# R7FA4L1BD register map
Vendor: Renesas Electronics Corporation; Series: RA4; File version: 0.90.02
CPU: CM33 r0p4, little endian, MPU, FPU, VTOR, 4 interrupt priority bits, 96 interrupts
Registers are 32-bit, read-write, reset 0x0 unless marked. A register's access mark holds for its fields unless they carry their own. Offsets are from the block's base; [hi:lo] are bit positions; 'fields as' and 'values as' point back to an identical list.

## SCI0 — Serial Communication Interface
Base 0x40118000
Same registers: SCI9 0x40118900
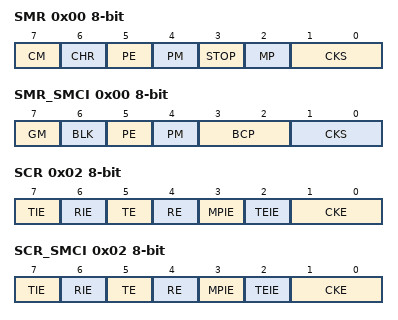
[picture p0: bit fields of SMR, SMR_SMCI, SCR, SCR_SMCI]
0x00 SMR 8-bit — Serial Mode Register for Non-Smart Card Interface Mode (SCMR.SMIF = 0)
  [7] CM — Communication Mode
    0=Asynchronous mode or simple IIC mode; 1=Clock synchronous mode or simple SPI mode
  [6] CHR — Character Length
    0=SCMR.CHR1 = 0: Transmit/receive in 9-bit data length SCMR.CHR1 = 1: Transmit/receive in 8-bit data length (initial value); 1=SCMR.CHR1 = 0: Transmit/receive in 9-bit data length SCMR.CHR1 = 1: Transmit/receive in 7-bit data length
  [5] PE — Parity Enable
    0=When transmitting: Do not add parity bit When receiving: Do not check parity bit; 1=When transmitting: Add parity bit When receiving: Check parity bit
  [4] PM — Parity Mode
    0=Even parity; 1=Odd parity
  [3] STOP — Stop Bit Length
    0=1 stop bit; 1=2 stop bits
  [2] MP — Multi-Processor Mode
    0=Disable multi-processor communications function; 1=Enable multi-processor communications function
  [1:0] CKS — Clock Select
    0=PCLK clock (n = 0); 1=PCLK/4 clock (n = 1); 2=PCLK/16 clock (n = 2); 3=PCLK/64 clock (n = 3)
0x00 SMR_SMCI 8-bit (alternate view of SMR) — Serial Mode Register for Smart Card Interface Mode (SCMR.SMIF = 1)
  [7] GM — GSM Mode
    0=Normal mode operation; 1=GSM mode operation
  [6] BLK — Block Transfer Mode
    0=Normal mode operation; 1=Block transfer mode operation
  [5] PE — Parity Enable
  [4] PM — Parity Mode
    0=Even parity; 1=Odd parity
  [3:2] BCP — Base Clock Pulse
  [1:0] CKS — Clock Select
    values as SMR.CKS
0x01 BRR 8-bit reset 0xFF — Bit Rate Register
0x02 SCR 8-bit — Serial Control Register for Non-Smart Card Interface Mode (SCMR.SMIF = 0)
  [7] TIE — Transmit Interrupt Enable
    0=Disable SCIn_TXI interrupt requests; 1=Enable SCIn_TXI interrupt requests
  [6] RIE — Receive Interrupt Enable
    0=Disable SCIn_RXI and SCIn_ERI interrupt requests; 1=Enable SCIn_RXI and SCIn_ERI interrupt requests
  [5] TE — Transmit Enable
    0=Disable serial transmission; 1=Enable serial transmission
  [4] RE — Receive Enable
    0=Disable serial reception; 1=Enable serial reception
  [3] MPIE — Multi-Processor Interrupt Enable
    0=Normal reception; 1=When data with the multi-processor bit set to 0 is received, the data is not read, and setting the status flags RDRF, ORER, and FER in SSR to 1 and the status flags SYER, PFER, and SBER in MESR are disabled. When data with the multi-processor bit set to 1 is received, the MPIE bit is automatically set to 0, and normal reception is resumed.
  [2] TEIE — Transmit End Interrupt Enable
    0=Disable SCIn_TEI interrupt requests; 1=Enable SCIn_TEI interrupt requests
  [1:0] CKE — Clock Enable
    0=In asynchronous mode, the SCKn pin is available for use as an I/O port based on the I/O port settings. In clock synchronous mode, the SCKn pin functions as the clock output pin.; 1=In asynchronous mode, a clock with the same frequency as the bit rate is output from the SCKn pin. In clock synchronous mode, the SCKn pin functions as the clock output pin.; other=Others (In asynchronous mode, input a clock with a frequency 16 times the bit rate from the SCKn pin when the SEMR.ABCS bit is 0. Input a clock signal with a frequency eight times the bit rate when the SEMR.ABCS bit is 1. The SCKn pin is available for use as an I/O port based on the I/O port settings when the GPT clock is used. In clock synchronous mode, the SCKn pin functions as the clock input pin.)
0x02 SCR_SMCI 8-bit (alternate view of SCR) — Serial Control Register for Smart Card Interface Mode (SCMR.SMIF = 1)
  [7] TIE — Transmit Interrupt Enable
    values as SCR.TIE
  [6] RIE — Receive Interrupt Enable
    values as SCR.RIE
  [5] TE — Transmit Enable
    0=Disable serial transmission; 1=Enable serial transmission
  [4] RE — Receive Enable
    0=Disable serial reception; 1=Enable serial reception
  [3] MPIE — Multi-Processor Interrupt Enable
  [2] TEIE — Transmit End Interrupt Enable
  [1:0] CKE — Clock Enable
    0=When SMR_SMCI.GM = 0: Disable output The SCKn pin is available for use as an I/O port if set up in the I/O port settings When SMR_SMCI.GM = 1: Fix output low; 1=When SMR_SMCI.GM = 0: Output clock When SMR_SMCI.GM = 1: Output clock; 2=When SMR_SMCI.GM = 0: Setting prohibited When SMR_SMCI.GM = 1: Fix output high; 3=When SMR_SMCI.GM = 0: Setting prohibited When SMR_SMCI.GM = 1: Output clock
0x03 TDR 8-bit reset 0xFF — Transmit Data Register
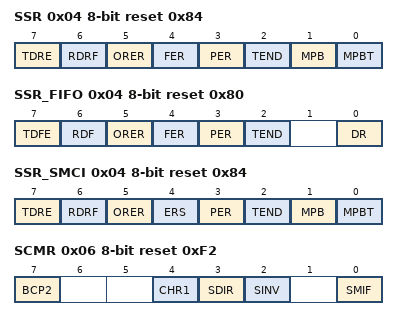
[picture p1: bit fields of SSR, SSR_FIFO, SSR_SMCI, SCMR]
0x04 SSR 8-bit reset 0x84 — Serial Status Register for Non-Smart Card Interface and Non-FIFO Mode (SCMR.SMIF = 0, FCR.FM = 0, and MMR.MANEN = 0)
  [7] TDRE — Transmit Data Empty Flag
    0=Transmit data in TDR register; 1=No transmit data in TDR register
  [6] RDRF — Receive Data Full Flag
    0=No received data in RDR register; 1=Received data in RDR register
  [5] ORER — Overrun Error Flag
    0=No overrun error occurred; 1=Overrun error occurred
  [4] FER — Framing Error Flag
    0=No framing error occurred; 1=Framing error occurred
  [3] PER — Parity Error Flag
    0=No parity error occurred; 1=Parity error occurred
  [2] TEND ro — Transmit End Flag
    0=A character is being transmitted; 1=Character transfer is complete
  [1] MPB ro — Multi-Processor
    0=Data transmission cycle; 1=ID transmission cycle
  [0] MPBT — Multi-Processor Bit Transfer
    0=Data transmission cycle; 1=ID transmission cycle
0x04 SSR_FIFO 8-bit reset 0x80 (alternate view of SSR) — Serial Status Register for Non-Smart Card Interface and FIFO Mode (SCMR.SMIF = 0, FCR.FM = 1, and MMR.MANEN = 0)
  [7] TDFE — Transmit FIFO Data Empty Flag
    0=The amount of transmit data written in FTDRHL exceeds the specified transmit triggering number; 1=The amount of transmit data written in FTDRHL is equal to or less than the specified transmit triggering number
  [6] RDF — Receive FIFO Data Full Flag
    0=The amount of receive data written in FRDRHL is less than the specified receive triggering number; 1=The amount of receive data written in FRDRHL is equal to or greater than the specified receive triggering number
  [5] ORER — Overrun Error Flag
    0=No overrun error occurred; 1=Overrun error occurred
  [4] FER — Framing Error Flag
    0=No framing error occurred; 1=Framing error occurred
  [3] PER — Parity Error Flag
    0=No parity error occurred; 1=Parity error occurred
  [2] TEND — Transmit End Flag
    values as SSR.TEND
  [0] DR — Receive Data Ready Flag
    0=Receiving is in progress, or no received data remains in FRDRHL after successfully completed reception (receive FIFO empty); 1=Next receive data is not received for a period after normal receiving is complete, when the amount of data stored in the FIFO is equal to or less than the receive triggering number
0x04 SSR_SMCI 8-bit reset 0x84 (alternate view of SSR) — Serial Status Register for Smart Card Interface Mode (SCMR.SMIF = 1, and MMR.MANEN = 0)
  [7] TDRE — Transmit Data Empty Flag
    values as SSR.TDRE
  [6] RDRF — Receive Data Full Flag
    values as SSR.RDRF
  [5] ORER — Overrun Error Flag
    0=No overrun error occurred; 1=Overrun error occurred
  [4] ERS — Error Signal Status Flag
    0=No low error signal response; 1=Low error signal response occurred
  [3] PER — Parity Error Flag
    0=No parity error occurred; 1=Parity error occurred
  [2] TEND ro — Transmit End Flag
    values as SSR.TEND
  [1] MPB ro — Multi-Processor
  [0] MPBT — Multi-Processor Bit Transfer
0x05 RDR 8-bit ro — Receive Data Register
0x06 SCMR 8-bit reset 0xF2 — Smart Card Mode Register
  [7] BCP2 — Base Clock Pulse 2
  [4] CHR1 — Character Length 1
    0=SMR.CHR = 0: Transmit/receive in 9-bit data length SMR.CHR = 1: Transmit/receive in 9-bit data length; 1=SMR.CHR = 0: Transmit/receive in 8-bit data length (initial value) SMR.CHR = 1: Transmit/receive in 7-bit data length
  [3] SDIR — Transmitted/Received Data Transfer Direction
    0=Transfer LSB-first; 1=Transfer MSB-first
  [2] SINV — Transmitted/Received Data Invert
    0=TDR contents are transmitted as they are. Received data is stored as received in the RDR register.; 1=TDR register contents are inverted before transmission. Receive data is stored in inverted form in the RDR register.
  [0] SMIF — Smart Card Interface Mode Select
    0=Non-smart card interface mode (asynchronous mode, clock synchronous mode, simple SPI mode, or simple IIC mode); 1=Smart card interface mode
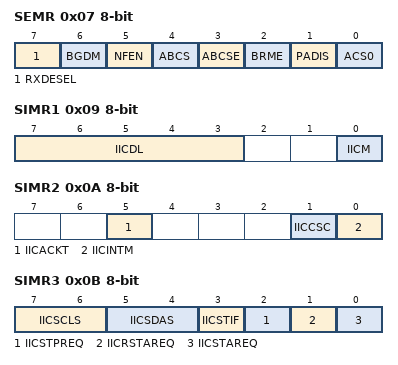
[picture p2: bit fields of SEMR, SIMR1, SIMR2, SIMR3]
0x07 SEMR 8-bit — Simple LIN Mode Register
  [7] RXDESEL — Asynchronous Start Bit Edge Detection Select
    0=Detect low level on RXDn pin as start bit; 1=Detect falling edge of RXDn pin as start bit
  [6] BGDM — Baud Rate Generator Double-Speed Mode Select
    0=Output clock from baud rate generator with normal frequency; 1=Output clock from baud rate generator with doubled frequency
  [5] NFEN — Digital Noise Filter Function Enable
    0=In asynchronous mode: Disable noise cancellation function for RXDn input signal In simple I2C mode: Disable noise cancellation function for SCLn and SDAn input signals; 1=In asynchronous mode: Enable noise cancellation function for RXDn input signal In simple I2C mode: Enable noise cancellation function for SCLn and SDAn input signals
  [4] ABCS — Asynchronous Mode Base Clock Select
    0=Select 16 base clock cycles for 1-bit period; 1=Select 8 base clock cycles for 1-bit period
  [3] ABCSE — Asynchronous Mode Extended Base Clock Select 1
    0=Clock cycles for 1-bit period determined by combination of the BGDM and ABCS bits in the SEMR register; 1=Baud rate is 6 base clock cycles for 1-bit period These bits for the other SCI channels than SCIn (n = 0, 3 to 5, 9) are reserved
  [2] BRME — Bit Rate Modulation Enable
    0=Disable bit rate modulation function; 1=Enable bit rate modulation function
  [1] PADIS — Preamble function Disable
    0=Preamble output function is enabled; 1=Preamble output function is disabled These bits for the other SCI channels than SCIn (n = 0, 3 to 5, 9) are reserved
  [0] ACS0 — Asynchronous Mode Clock Source Select
    0=External clock input; 1=Logical AND of compare matches output from the internal GPT. These bit for the other SCI channels than SCIn (n = 1) are reserved.
0x08 SNFR 8-bit — Noise Filter Setting Register
  [2:0] NFCS — Noise Filter Clock Select
    0=In asynchronous mode: Use clock signal divided by 1 with noise filter In simple I2C mode: Setting prohibited; 1=In asynchronous mode: Setting prohibited In simple I2C mode: Use clock signal divided by 1 with noise filter; 2=In asynchronous mode: Setting prohibited In simple I2C mode: Use clock signal divided by 2 with noise filter; 3=In asynchronous mode: Setting prohibited In simple I2C mode: Use clock signal divided by 4 with noise filter; 4=In asynchronous mode: Setting prohibited In simple I2C mode: Use clock signal divided by 8 with noise filter; other=Others (Setting prohibited)
0x09 SIMR1 8-bit — IIC Mode Register 1
  [7:3] IICDL — SDAn Delay Output Select
    0=No output delay; other=Others ((IICDL - 1) to (IICDL) cycles)
  [0] IICM — Simple IIC Mode Select
    0=SCMR.SMIF = 0: Asynchronous mode (including multi-processor mode), clock synchronous mode, or simple SPI mode SCMR.SMIF = 1: Smart card interface mode; 1=SCMR.SMIF = 0: Simple IIC mode SCMR.SMIF = 1: Setting prohibited
0x0A SIMR2 8-bit — IIC Mode Register 2
  [5] IICACKT — ACK Transmission Data
    0=ACK transmission; 1=NACK transmission and ACK/NACK reception
  [1] IICCSC — Clock Synchronization
    0=Do not synchronize with clock signal; 1=Synchronize with clock signal
  [0] IICINTM — IIC Interrupt Mode Select
    0=Use ACK/NACK interrupts; 1=Use reception and transmission interrupts
0x0B SIMR3 8-bit — IIC Mode Register 3
  [7:6] IICSCLS — SCLn Output Select
    0=Output serial clock; 1=Generate start, restart, or stop condition; 2=Output low on SCLn pin; 3=Drive SCLn pin to high-impedance state
  [5:4] IICSDAS — SDAn Output Select
    0=Output serial data; 1=Generate start, restart, or stop condition; 2=Output low on SDAn pin; 3=Drive SDAn pin to high-impedance state
  [3] IICSTIF — Issuing of Start, Restart, or Stop Condition Completed Flag
    0=No requests are being made for generating conditions, or a condition is being generated; 1=Generation of start, restart, or stop condition is complete. When 0 is written to IICSTIF, it is set to 0
  [2] IICSTPREQ — Stop Condition Generation
    0=Do not generate stop condition; 1=Generate stop condition
  [1] IICRSTAREQ — Restart Condition Generation
    0=Do not generate restart condition; 1=Generate restart condition
  [0] IICSTAREQ — Start Condition Generation
    0=Do not generate start condition; 1=Generate start condition
0x0C SISR 8-bit ro — IIC Status Register
  [0] IICACKR — ACK Reception Data Flag
    0=ACK received; 1=NACK received
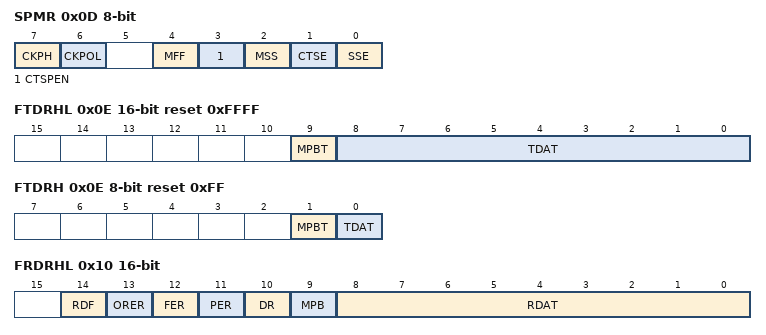
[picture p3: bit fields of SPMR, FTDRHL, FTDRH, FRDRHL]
0x0D SPMR 8-bit — SPI Mode Register
  [7] CKPH — Clock Phase Select
    0=Do not delay clock; 1=Delay clock
  [6] CKPOL — Clock Polarity Select
    0=Do not invert clock polarity; 1=Invert clock polarity
  [4] MFF — Mode Fault Flag
    0=No mode fault error; 1=Mode fault error
  [3] CTSPEN — CTS External Pin Enable
    0=Alternate setting to use CTS and RTS functions as either one terminal; 1=Dedicated setting for separately using CTS and RTS functions with 2 terminals These bits for the other SCI channels than SCIn (n = 0, 3 to 5, 9) are reserved
  [2] MSS — Master Slave Select
    0=Transmit through TXDn pin and receive through RXDn pin (master mode); 1=Receive through TXDn pin and transmit through RXDn pin (slave mode)
  [1] CTSE — CTS Enable
    0=Disable CTS function (enable RTS output function); 1=Enable CTS function
  [0] SSE — SSn Pin Function Enable
    0=Disable SSn pin function; 1=Enable SSn pin function
0x0E FTDRHL 16-bit wo reset 0xFFFF — Transmit FIFO Data Register
  [9] MPBT — Multi-Processor Transfer Bit Flag
    0=Data transmission cycle; 1=ID transmission cycle
  [8:0] TDAT — Serial Transmit Data
0x0E TDRHL 16-bit reset 0xFFFF (alternate view of FTDRHL) — Transmit Data Register for Non-Manchester Mode (MMR.MANEN = 0)
  [8:0] TDAT — Serial Transmit Data
0x0E FTDRH 8-bit wo reset 0xFF (alternate view of FTDRHL) — Transmit FIFO Data Register
  [1] MPBT — Multi-Processor Transfer Bit Flag
    0=Data transmission cycle; 1=ID transmission cycle
  [0] TDAT — Serial Transmit Data
0x0F FTDRL 8-bit wo reset 0xFF (alternate view of FTDRHL) — Transmit FIFO Data Register
  [7:0] TDAT — Serial Transmit Data
0x10 FRDRHL 16-bit ro — Receive FIFO Data Register
  [14] RDF — Receive FIFO Data Full Flag
    0=The amount of receive data written in FRDRH and FRDRL is less than the specified receive triggering number; 1=The amount of receive data written in FRDRH and FRDRL is equal to or greater than the specified receive triggering number
  [13] ORER — Overrun Error Flag
    0=No overrun error occurred; 1=Overrun error occurred
  [12] FER — Framing Error Flag
    0=No framing error occurred in the first data of FRDRH and FRDRL; 1=Framing error occurred in the first data of FRDRH and FRDRL
  [11] PER — Parity Error Flag
    0=No parity error occurred in the first data of FRDRH and FRDRL; 1=Parity error occurred in the first data of FRDRH and FRDRL
  [10] DR — Receive Data Ready Flag
    0=Receiving is in progress, or no received data remains in the FRDRH and FRDRL registers after successfully completed reception; 1=Next receive data is not received for a period after successfully completed reception
  [9] MPB — Multi-Processor Bit Flag
    0=Data transmission cycle; 1=ID transmission cycle
  [8:0] RDAT — Serial receive data
0x10 RDRHL 16-bit ro (alternate view of FRDRHL) — Receive Data Register for Non-Manchester Mode (MMR.MANEN = 0)
  [8:0] RDAT — Serial Receive Data
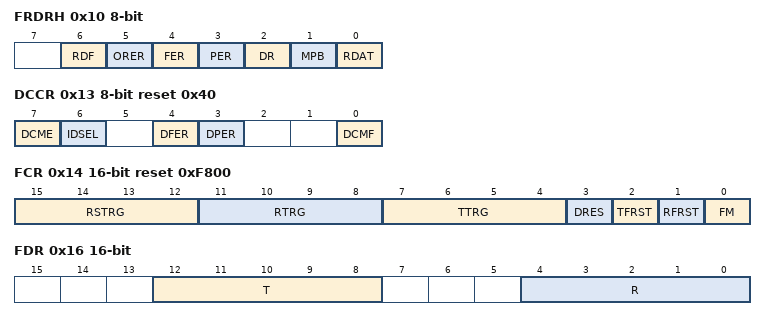
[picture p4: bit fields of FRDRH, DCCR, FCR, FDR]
0x10 FRDRH 8-bit ro (alternate view of FRDRHL) — Receive FIFO Data Register
  [6] RDF — Receive FIFO Data Full Flag
    values as FRDRHL.RDF
  [5] ORER — Overrun Error Flag
    0=No overrun error occurred; 1=Overrun error occurred
  [4] FER — Framing Error Flag
    values as FRDRHL.FER
  [3] PER — Parity Error Flag
    values as FRDRHL.PER
  [2] DR — Receive Data Ready Flag
    values as FRDRHL.DR
  [1] MPB — Multi-Processor Bit Flag
    0=Data transmission cycle; 1=ID transmission cycle
  [0] RDAT — Serial receive data
0x11 FRDRL 8-bit ro (alternate view of FRDRHL) — Receive FIFO Data Register
  [7:0] RDAT — Serial receive data
0x12 MDDR 8-bit reset 0xFF — Modulation Duty Register
0x13 DCCR 8-bit reset 0x40 — Data Compare Match Control Register
  [7] DCME — Data Compare Match Enable
    0=Disable address match function; 1=Enable address match function
  [6] IDSEL — ID Frame Select
    0=Always compare data regardless of the MPB bit value; 1=Only compare data when MPB bit = 1 (ID frame)
  [4] DFER — Data Compare Match Framing Error Flag
    0=No framing error occurred; 1=Framing error occurred
  [3] DPER — Data Compare Match Parity Error Flag
    0=No parity error occurred; 1=Parity error occurred
  [0] DCMF — Data Compare Match Flag
    0=Not matched; 1=Matched
0x14 FCR 16-bit reset 0xF800 — FIFO Control Register
  [15:12] RSTRG — RTS Output Active Trigger Number Select
  [11:8] RTRG — Receive FIFO Data Trigger Number
  [7:4] TTRG — Transmit FIFO Data Trigger Number
  [3] DRES — Receive Data Ready Error Select
    0=Receive data full interrupt (SCIn_RXI); 1=Receive error interrupt (SCIn_ERI)
  [2] TFRST — Transmit FIFO Data Register Reset
    0=Do not reset FTDRHL; 1=Reset FTDRHL
  [1] RFRST — Receive FIFO Data Register Reset
    0=Do not reset FRDRHL; 1=Reset FRDRHL
  [0] FM — FIFO Mode Select
    0=Non-FIFO mode. Selects TDR/RDR or TDRHL/RDRHL for communication.; 1=FIFO mode. Selects FTDRHL/FRDRHL for communication.
0x16 FDR 16-bit ro — FIFO Data Count Register
  [12:8] T — Transmit FIFO Data Count
  [4:0] R — Receive FIFO Data Count
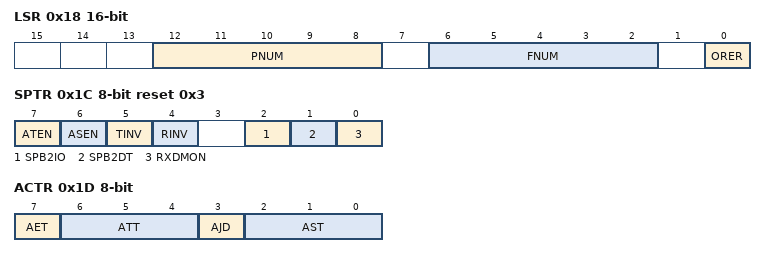
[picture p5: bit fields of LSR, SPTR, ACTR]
0x18 LSR 16-bit ro — Line Status Register
  [12:8] PNUM — Parity Error Count
  [6:2] FNUM — Framing Error Count
  [0] ORER — Overrun Error Flag
    0=No overrun error occurred; 1=Overrun error occurred
0x1A CDR 16-bit — Compare Match Data Register
  [8:0] CMPD — Compare Match Data
0x1C SPTR 8-bit reset 0x3 — Serial Port Register
  [7] ATEN — Adjust Transmit Timing Enable
    0=Adjust transmit timing disable; 1=Adjust transmit timing enable
  [6] ASEN — Adjust Receive Sampling Timing Enable
    0=Adjust sampling timing disable; 1=Adjust sampling timing enable
  [5] TINV — TXD Invert Bit
    0=Transmit data is not inverted and output to TXDn; 1=Transmit data is inverted and output to TXDn
  [4] RINV — RXD Invert Bit
    0=Received data from RXDn is not inverted and input; 1=Received data from RXDn is inverted and input
  [2] SPB2IO — Serial Port Break I/O
    0=Do not output value of SPB2DT bit on TXDn pin; 1=Output value of SPB2DT bit on TXDn pin
  [1] SPB2DT — Serial Port Break Data Select
    0=When TINV = 0, low level is output in TXDn terminal. When TINV = 1, high level is output in TXDn terminal.; 1=When TINV = 0, high level is output in TXDn terminal. When TINV = 1, low level is output in TXDn terminal.
  [0] RXDMON ro — Serial Input Data Monitor
    0=When RINV = 0, RXDn terminal is the low level. When RINV = 1, RXDn terminal is the high level.; 1=When RINV = 0, RXDn terminal is the high level. When RINV = 1, RXDn terminal is the low level.
0x1D ACTR 8-bit — Adjustment Communication Timing Register
  [7] AET — Adjustment Edge for Transmit Timing
    0=Adjust the rising edge timing; 1=Adjust the falling edge timing
  [6:4] ATT — Adjustment Value for Transmit Timing
  [3] AJD — Adjustment Direction for Receive Sampling Timing
    0=The sampling timing is adjusted backward to the middle of bit; 1=The sampling timing is adjusted forward to the middle of bit
  [2:0] AST — Adjustment Value for Receive Sampling Timing

## SCI3 — Serial Communication Interface
Base 0x40118300
Same registers: SCI4 0x40118400
Registers as SCI0; these are added or differ:
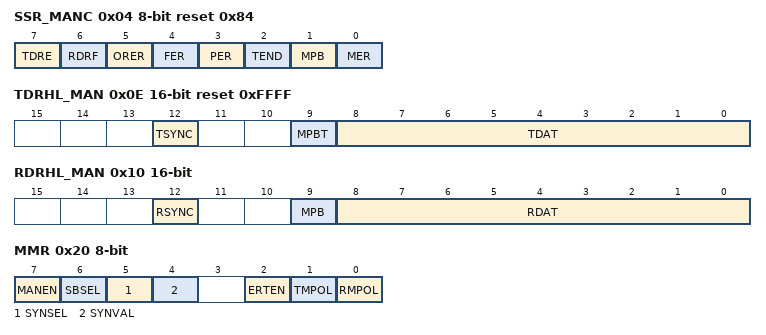
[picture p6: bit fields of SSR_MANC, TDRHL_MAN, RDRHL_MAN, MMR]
0x04 SSR_MANC 8-bit reset 0x84 (alternate view of SSR) — Serial Status Register for Manchester Mode (SCMR.SMIF = 0, and MMR.MANEN = 1)
  [7] TDRE — Transmit Data Empty Flag
    0=Transmit data is in TDR register; 1=No transmit data is in TDR register
  [6] RDRF — Receive Data Full Flag
    0=No received data is in RDR register; 1=Received data is in RDR register
  [5] ORER — Overrun Error Flag
    0=No overrun error occurred; 1=An overrun error has occurred
  [4] FER — Framing Error Flag
    0=No framing error occurred; 1=A framing error has occurred
  [3] PER — Parity Error Flag
    0=No parity error occurred; 1=A parity error has occurred
  [2] TEND ro — Transmit End Flag
    0=A character is being transmitted; 1=Character transfer has been completed
  [1] MPB ro — Multi-Processor
    0=Data transmission cycles; 1=ID transmission cycles
  [0] MER — Manchester Error Flag
    0=No Manchester error occurred; 1=Manchester error has occurred
0x0E TDRHL_MAN 16-bit reset 0xFFFF (alternate view of FTDRHL) — Transmit Data Register for Manchester Mode (MMR.MANEN = 1)
  [12] TSYNC — Transmit SYNC data bit
    0=The Start bit is transmitted as DATA SYNC; 1=The Start bit is transmitted as COMMAND SYNC
  [9] MPBT — Multi-processor Transfer Bit Flag
    0=Data transmission cycles; 1=ID transmission cycles
  [8:0] TDAT — Serial Transmit Data
0x10 RDRHL_MAN 16-bit ro (alternate view of FRDRHL) — Receive Data Register for Manchester Mode (MMR.MANEN = 1)
  [12] RSYNC — Receive SYNC Data Bit
    0=The received Start bit is DATA SYNC; 1=The received Start bit is COMMAND SYNC
  [9] MPB — Multi-processor Bit
    0=Data transmission cycles; 1=ID transmission cycles
  [8:0] RDAT — Serial Receive Data
0x20 MMR 8-bit — Manchester Mode Register
  [7] MANEN — Manchester Mode Enable
    0=Disables the Manchester mode; 1=Enables the Manchester mode
  [6] SBSEL — Start Bit Select
    0=The start bit area consists of one bit; 1=The start bit area consists of three bits (COMMAND SYNC or DATA SYNC)
  [5] SYNSEL — SYNC Select
    0=The start bit pattern is set with the SYNVAL bit; 1=The start bit pattern is set with the TSYNC bit
  [4] SYNVAL — SYNC Value Setting
    0=The start bit is added as a zero-to-one transition; 1=The start bit is added as a one-to-zero transition
  [2] ERTEN — Manchester Edge Retiming Enable
    0=Disables the receive retiming function; 1=Enables the receive retiming function
  [1] TMPOL — Polarity of Transmit Manchester Code
    0=Logic 0 is coded as a zero-to-one transition in Manchester code Logic 1 is coded as a one-to-zero transition in Manchester code; 1=Logic 0 is coded as a one-to-zero transition in Manchester code Logic 1 is coded as a zero-to-one transition in Manchester code
  [0] RMPOL — Polarity of Received Manchester Code
    values as TMPOL
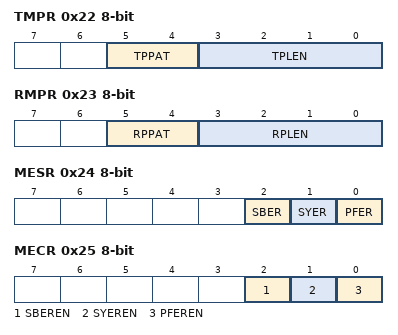
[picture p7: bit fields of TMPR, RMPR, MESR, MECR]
0x22 TMPR 8-bit — Transmit Manchester Preface Setting Register
  [5:4] TPPAT — Transmit Preface Pattern
    0=All zeros; 1=Zero one; 2=One zero; 3=All ones
  [3:0] TPLEN — Transmit Preface Length
    0=Disables the transmit preface generation; other=Others (Transmit preface length (bit length))
0x23 RMPR 8-bit — Receive Manchester Preface Setting Register
  [5:4] RPPAT — Receive Preface Pattern
    0=All zeros; 1=Zero one; 2=One zero; 3=All ones
  [3:0] RPLEN — Receive Preface Length
    0=Disables the receive preface generation; other=Others (Receive preface length (bit length))
0x24 MESR 8-bit — Manchester Extended Error Status Register
  [2] SBER — Start Bit Error Flag
    0=No start bit error detected; 1=Start bit error detected
  [1] SYER — SYNC Error Flag
    0=No receive SYNC error detected; 1=Receive SYNC error detected
  [0] PFER — Preface Error Flag
    0=No preface error detected; 1=Preface error detected
0x25 MECR 8-bit — Manchester Extended Error Control Register
  [2] SBEREN — Start Bit Error Enable
    0=Does not handle a start bit error as an interrupt source; 1=Handles a start bit error as an interrupt source
  [1] SYEREN — Receive SYNC Error Enable
    0=Does not handle a receive SYNC error as an interrupt source; 1=Handles a receive SYNC error as an interrupt source
  [0] PFEREN — Preface Error Enable
    0=Does not handle a preface error as an interrupt source; 1=Handles a preface error as an interrupt source

## SCI5 — Serial Communication Interface
Base 0x40118500
Registers as SCI0; these are added or differ:
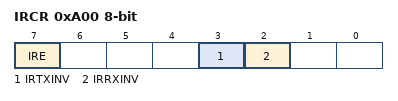
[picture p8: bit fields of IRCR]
0xA00 IRCR 8-bit — IrDA Control Register
  [7] IRE — IrDA Enable
    0=Use serial input/output pins for normal serial communication; 1=Use serial input/output pins for IrDA data communication
  [3] IRTXINV — IRTXD Polarity Switching
    0=Output transmitted data to IRTXD pin as is; 1=Output transmitted data to IRTXD pin after the polarity is inverted
  [2] IRRXINV — IRRXD Polarity Switching
    0=Use input from IRRXD pin as received data as is; 1=Use input from IRRXD pin as received data after the polarity is inverted
